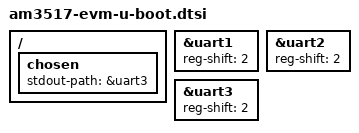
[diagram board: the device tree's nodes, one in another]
// SPDX-License-Identifier: GPL-2.0+
/*
 * Copyright (C) 2017
 * Logic PD - http://www.logicpd.com
 */

/ {
	chosen {
		stdout-path = &uart3;
	};
};

&uart1 {
	reg-shift = <2>;
};

&uart2 {
	reg-shift = <2>;
};

&uart3 {
	reg-shift = <2>;
};
